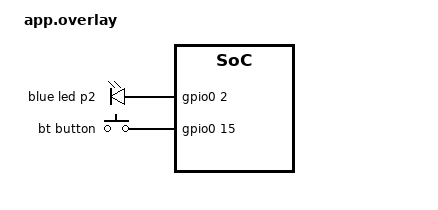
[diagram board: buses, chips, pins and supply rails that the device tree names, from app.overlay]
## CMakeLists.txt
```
 cmake_minimum_required(VERSION 3.26.3)

 set(BOARD esp32)

 find_package(Zephyr REQUIRED HINTS $ENV{ZEPHYR_BASE})
 
 project(bt)

 target_sources(app PRIVATE src/main.c  bt/bt.c  src/user_gpio.c)
```

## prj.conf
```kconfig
CONFIG_GPIO=y
CONFIG_LOG=y
CONFIG_PRINTK=y
CONFIG_LOG=y
CONFIG_FPU=y
# multithreading options
CONFIG_TIMESLICING=y
CONFIG_TIMESLICE_SIZE=10
#flash storage options 
CONFIG_NVS=y

#bluetooth configurations
CONFIG_BT=y
CONFIG_BT_DEVICE_NAME="junior"
CONFIG_BT_PERIPHERAL=y
CONFIG_BT_GATT_CLIENT=y
CONFIG_BT_PERIPHERAL_PREF_MAX_INT=800
CONFIG_BT_PERIPHERAL_PREF_MIN_INT=400
CONFIG_BT_PERIPHERAL_PREF_TIMEOUT=400
CONFIG_BT_GAP_AUTO_UPDATE_CONN_PARAMS=y
# bluetooth phy configurations 
```

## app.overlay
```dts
/{
    
    leds{
        compatible="gpio-leds";
         blue: blue{
            gpios=<&gpio0 2 GPIO_ACTIVE_HIGH>;
            label="blue led p2";
         };
      };
    buttons
     {
        blue_hat:blue_hat
        {
          gpios=<&gpio0 15  (GPIO_PULL_UP|GPIO_ACTIVE_HIGH)>; 
          label="bt button";   
        };
      };
   aliases{
      ble=&blue;
      buttony=&blue_hat;
 };
   
};
```

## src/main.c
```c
#include"../inc/primary_deps.h"
#include"../bt/bt.h"

 LOG_MODULE_REGISTER(bt,LOG_LEVEL_DBG);


int main()
{  

  if(!gpio_init()){
    return 1;
  }
    int err;
  err=bluetooth_init();
       if(err){
        return 1;
       }
       
    return 0;
}
```

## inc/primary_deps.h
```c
#pragma once

// zephyr main dependancies
#include<zephyr/kernel.h>
#include<zephyr/device.h>
#include<zephyr/sys/printk.h>
#include<zephyr/logging/log.h>
#include<zephyr/drivers/gpio.h>
#include<zephyr/devicetree.h>

bool gpio_init();
```

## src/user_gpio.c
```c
#include"../inc/primary_deps.h"
#include"../bt/bt.h"

// gpio pointe to device tree node
// external usage of this in bt.c
struct gpio_dt_spec  blue=GPIO_DT_SPEC_GET(DT_ALIAS(ble),gpios);
//external usage in bt.c app/bt/bt.c
struct gpio_dt_spec button=GPIO_DT_SPEC_GET(DT_ALIAS(buttony),gpios);
LOG_MODULE_DECLARE(bt,LOG_LEVEL_DBG);
 struct gpio_callback cb;
 // external variable from app/bt/bt.c
 extern int button_state;
void button_pressed(const struct device *port,
					struct gpio_callback *cb,
					gpio_port_pins_t pins){
             LOG_DBG("running interrupt \n");
    send_button_state_indicate(button_state);
    return;

 }
bool gpio_init(){

    if(!gpio_is_ready_dt(&blue)){
        LOG_ERR(" gpio %u is not ready for use",blue.pin);
        return false;
    }
    if(!gpio_is_ready_dt(&button))
    {
        LOG_ERR(" gpio_ pin %u connected to yellow button",button.pin);
        return false;
    }
    gpio_pin_configure_dt(&blue,GPIO_OUTPUT_ACTIVE);
    gpio_pin_configure_dt(&button,GPIO_INPUT);

    for(uint8_t i;i<10;++i){
    gpio_pin_toggle_dt(&blue);
    k_msleep(100);
    gpio_pin_toggle_dt(&blue);
    k_msleep(100);
    }
    
  
  gpio_pin_interrupt_configure_dt(&button,GPIO_INT_EDGE_BOTH);
  gpio_init_callback(&cb,button_pressed,BIT(button.pin));
  gpio_add_callback_dt(&button,&cb);
  
  return true;
    
}
```
